# ESP32 register map
Vendor: ESPRESSIF SYSTEMS (SHANGHAI) CO., LTD.; Series: ESP32 Series; File version: 17
CPU: Xtensa LX6 r0p0, little endian, no MPU, FPU, 0 interrupt priority bits
Address unit: 32 bits
Registers are 32-bit, read-write, reset 0x0 unless marked. A register's access mark holds for its fields unless they carry their own. Offsets are from the block's base; [hi:lo] are bit positions; {n}, {i} and the like mark numbered series.

## SLCHOST — SLCHOST Peripheral
Base 0x3FF55000
0x10 HOST_SLCHOST_FUNC2_0
  [24] HOST_SLC_FUNC2_INT
0x14 HOST_SLCHOST_FUNC2_1
  [0] HOST_SLC_FUNC2_INT_EN
0x20 HOST_SLCHOST_FUNC2_2 reset 0x1
  [0] HOST_SLC_FUNC1_MDSTAT
0x34 HOST_SLCHOST_GPIO_STATUS0 ro
  [31:0] HOST_GPIO_SDIO_INT0
0x38 HOST_SLCHOST_GPIO_STATUS1 ro
  [7:0] HOST_GPIO_SDIO_INT1
0x3C HOST_SLCHOST_GPIO_IN0 ro
  [31:0] HOST_GPIO_SDIO_IN0
0x40 HOST_SLCHOST_GPIO_IN1 ro
  [7:0] HOST_GPIO_SDIO_IN1
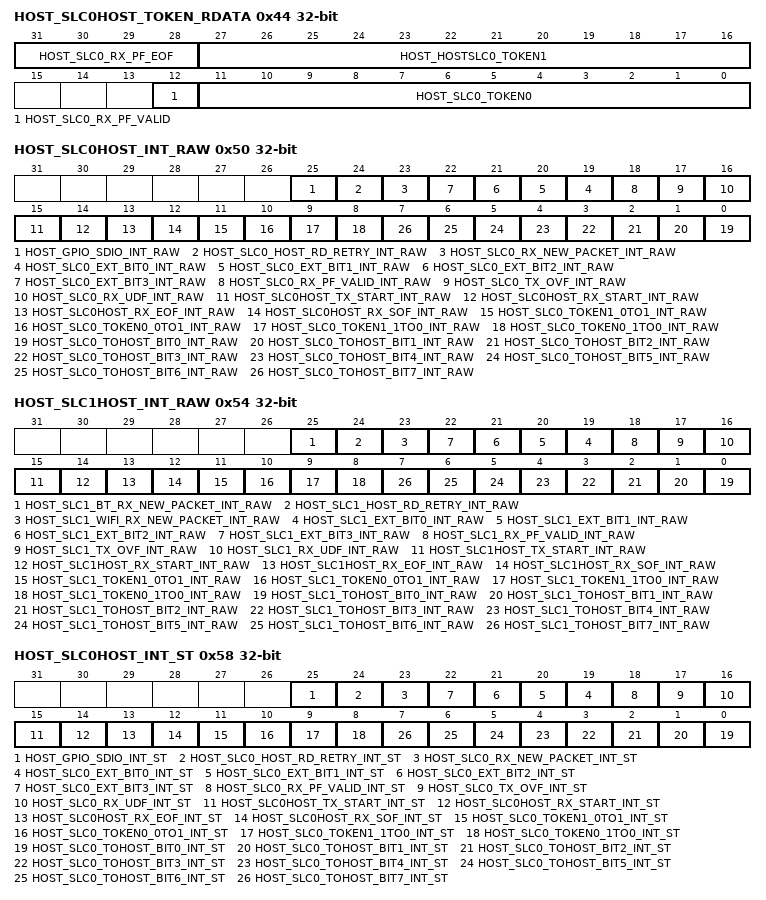
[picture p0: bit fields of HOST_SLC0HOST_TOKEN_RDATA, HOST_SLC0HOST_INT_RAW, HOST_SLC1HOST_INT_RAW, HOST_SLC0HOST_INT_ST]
0x44 HOST_SLC0HOST_TOKEN_RDATA ro
  [31:28] HOST_SLC0_RX_PF_EOF, [27:16] HOST_HOSTSLC0_TOKEN1, [12] HOST_SLC0_RX_PF_VALID, [11:0] HOST_SLC0_TOKEN0
0x48 HOST_SLC0_HOST_PF ro
  [31:0] HOST_SLC0_PF_DATA
0x4C HOST_SLC1_HOST_PF ro
  [31:0] HOST_SLC1_PF_DATA
0x50 HOST_SLC0HOST_INT_RAW ro
  [25] HOST_GPIO_SDIO_INT_RAW, [24] HOST_SLC0_HOST_RD_RETRY_INT_RAW, [23] HOST_SLC0_RX_NEW_PACKET_INT_RAW, [n+19] HOST_SLC0_EXT_BIT{n}_INT_RAW (n=0..3), [18] HOST_SLC0_RX_PF_VALID_INT_RAW, [17] HOST_SLC0_TX_OVF_INT_RAW, [16] HOST_SLC0_RX_UDF_INT_RAW, [15] HOST_SLC0HOST_TX_START_INT_RAW, [14] HOST_SLC0HOST_RX_START_INT_RAW, [13] HOST_SLC0HOST_RX_EOF_INT_RAW, [12] HOST_SLC0HOST_RX_SOF_INT_RAW, [11] HOST_SLC0_TOKEN1_0TO1_INT_RAW, [10] HOST_SLC0_TOKEN0_0TO1_INT_RAW, [9] HOST_SLC0_TOKEN1_1TO0_INT_RAW, [8] HOST_SLC0_TOKEN0_1TO0_INT_RAW, [n] HOST_SLC0_TOHOST_BIT{n}_INT_RAW (n=0..7)
0x54 HOST_SLC1HOST_INT_RAW ro
  [25] HOST_SLC1_BT_RX_NEW_PACKET_INT_RAW, [24] HOST_SLC1_HOST_RD_RETRY_INT_RAW, [23] HOST_SLC1_WIFI_RX_NEW_PACKET_INT_RAW, [n+19] HOST_SLC1_EXT_BIT{n}_INT_RAW (n=0..3), [18] HOST_SLC1_RX_PF_VALID_INT_RAW, [17] HOST_SLC1_TX_OVF_INT_RAW, [16] HOST_SLC1_RX_UDF_INT_RAW, [15] HOST_SLC1HOST_TX_START_INT_RAW, [14] HOST_SLC1HOST_RX_START_INT_RAW, [13] HOST_SLC1HOST_RX_EOF_INT_RAW, [12] HOST_SLC1HOST_RX_SOF_INT_RAW, [11] HOST_SLC1_TOKEN1_0TO1_INT_RAW, [10] HOST_SLC1_TOKEN0_0TO1_INT_RAW, [9] HOST_SLC1_TOKEN1_1TO0_INT_RAW, [8] HOST_SLC1_TOKEN0_1TO0_INT_RAW, [n] HOST_SLC1_TOHOST_BIT{n}_INT_RAW (n=0..7)
0x58 HOST_SLC0HOST_INT_ST ro
  [25] HOST_GPIO_SDIO_INT_ST, [24] HOST_SLC0_HOST_RD_RETRY_INT_ST, [23] HOST_SLC0_RX_NEW_PACKET_INT_ST, [n+19] HOST_SLC0_EXT_BIT{n}_INT_ST (n=0..3), [18] HOST_SLC0_RX_PF_VALID_INT_ST, [17] HOST_SLC0_TX_OVF_INT_ST, [16] HOST_SLC0_RX_UDF_INT_ST, [15] HOST_SLC0HOST_TX_START_INT_ST, [14] HOST_SLC0HOST_RX_START_INT_ST, [13] HOST_SLC0HOST_RX_EOF_INT_ST, [12] HOST_SLC0HOST_RX_SOF_INT_ST, [11] HOST_SLC0_TOKEN1_0TO1_INT_ST, [10] HOST_SLC0_TOKEN0_0TO1_INT_ST, [9] HOST_SLC0_TOKEN1_1TO0_INT_ST, [8] HOST_SLC0_TOKEN0_1TO0_INT_ST, [n] HOST_SLC0_TOHOST_BIT{n}_INT_ST (n=0..7)
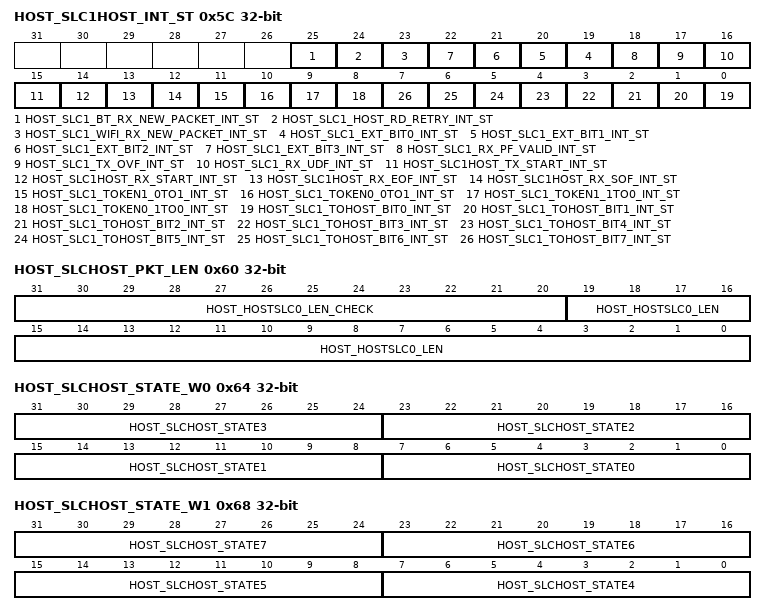
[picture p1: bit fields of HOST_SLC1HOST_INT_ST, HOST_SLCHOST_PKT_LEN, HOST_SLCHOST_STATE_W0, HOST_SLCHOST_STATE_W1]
0x5C HOST_SLC1HOST_INT_ST ro
  [25] HOST_SLC1_BT_RX_NEW_PACKET_INT_ST, [24] HOST_SLC1_HOST_RD_RETRY_INT_ST, [23] HOST_SLC1_WIFI_RX_NEW_PACKET_INT_ST, [n+19] HOST_SLC1_EXT_BIT{n}_INT_ST (n=0..3), [18] HOST_SLC1_RX_PF_VALID_INT_ST, [17] HOST_SLC1_TX_OVF_INT_ST, [16] HOST_SLC1_RX_UDF_INT_ST, [15] HOST_SLC1HOST_TX_START_INT_ST, [14] HOST_SLC1HOST_RX_START_INT_ST, [13] HOST_SLC1HOST_RX_EOF_INT_ST, [12] HOST_SLC1HOST_RX_SOF_INT_ST, [11] HOST_SLC1_TOKEN1_0TO1_INT_ST, [10] HOST_SLC1_TOKEN0_0TO1_INT_ST, [9] HOST_SLC1_TOKEN1_1TO0_INT_ST, [8] HOST_SLC1_TOKEN0_1TO0_INT_ST, [n] HOST_SLC1_TOHOST_BIT{n}_INT_ST (n=0..7)
0x60 HOST_SLCHOST_PKT_LEN ro
  [31:20] HOST_HOSTSLC0_LEN_CHECK, [19:0] HOST_HOSTSLC0_LEN
0x64 HOST_SLCHOST_STATE_W0 ro
  [8n+7:8n] HOST_SLCHOST_STATE{n} (n=0..3)
0x68 HOST_SLCHOST_STATE_W1 ro
  [8n-25:8n-32] HOST_SLCHOST_STATE{n} (n=4..7)
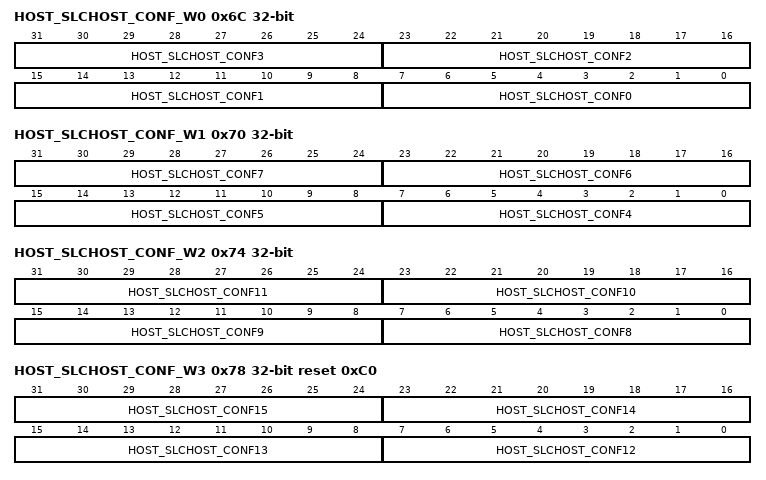
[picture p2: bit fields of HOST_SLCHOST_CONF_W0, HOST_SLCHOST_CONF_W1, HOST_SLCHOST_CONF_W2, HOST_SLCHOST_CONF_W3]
0x6C HOST_SLCHOST_CONF_W0
  [8n+7:8n] HOST_SLCHOST_CONF{n} (n=0..3)
0x70 HOST_SLCHOST_CONF_W1
  [8n-25:8n-32] HOST_SLCHOST_CONF{n} (n=4..7)
0x74 HOST_SLCHOST_CONF_W2
  [8n-57:8n-64] HOST_SLCHOST_CONF{n} (n=8..11)
0x78 HOST_SLCHOST_CONF_W3 reset 0xC0
  [8n-89:8n-96] HOST_SLCHOST_CONF{n} (n=12..15)
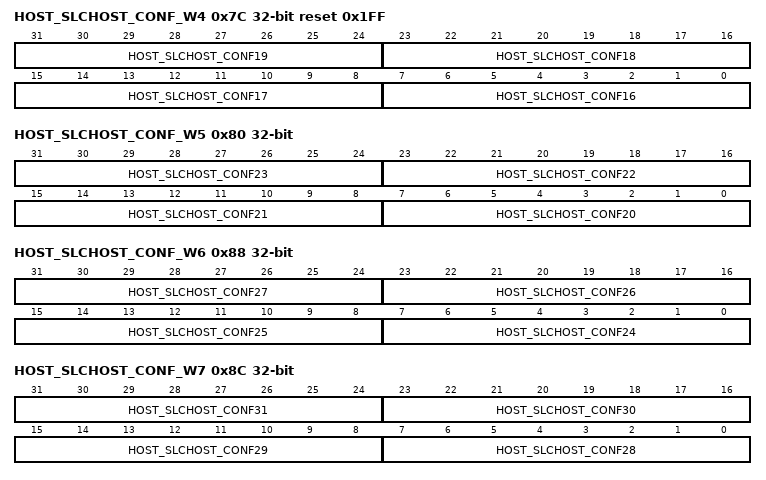
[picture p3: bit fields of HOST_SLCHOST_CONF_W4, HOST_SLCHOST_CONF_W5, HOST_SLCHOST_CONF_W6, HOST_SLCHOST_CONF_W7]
0x7C HOST_SLCHOST_CONF_W4 reset 0x1FF
  [31:24] HOST_SLCHOST_CONF19 — Interrupt to target CPU
  [23:16] HOST_SLCHOST_CONF18
  [15:8] HOST_SLCHOST_CONF17 — SLC timeout enable
  [7:0] HOST_SLCHOST_CONF16 — SLC timeout value
0x80 HOST_SLCHOST_CONF_W5
  [8n-153:8n-160] HOST_SLCHOST_CONF{n} (n=20..23)
0x84 HOST_SLCHOST_WIN_CMD access not given
0x88 HOST_SLCHOST_CONF_W6
  [8n-185:8n-192] HOST_SLCHOST_CONF{n} (n=24..27)
0x8C HOST_SLCHOST_CONF_W7
  [8n-217:8n-224] HOST_SLCHOST_CONF{n} (n=28..31)
{0x90+4i} HOST_SLCHOST_PKT_LEN{i} ro (i=0..2)
  [19:0] HOST_HOSTSLC0_LEN{i}
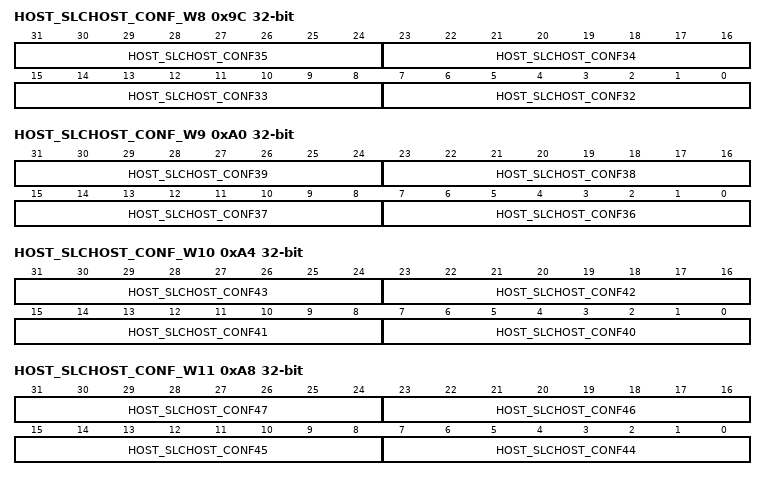
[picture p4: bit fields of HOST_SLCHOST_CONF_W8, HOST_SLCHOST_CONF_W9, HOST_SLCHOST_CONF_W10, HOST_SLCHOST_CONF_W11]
0x9C HOST_SLCHOST_CONF_W8
  [8n-249:8n-256] HOST_SLCHOST_CONF{n} (n=32..35)
0xA0 HOST_SLCHOST_CONF_W9
  [8n-281:8n-288] HOST_SLCHOST_CONF{n} (n=36..39)
0xA4 HOST_SLCHOST_CONF_W10
  [8n-313:8n-320] HOST_SLCHOST_CONF{n} (n=40..43)
0xA8 HOST_SLCHOST_CONF_W11
  [8n-345:8n-352] HOST_SLCHOST_CONF{n} (n=44..47)
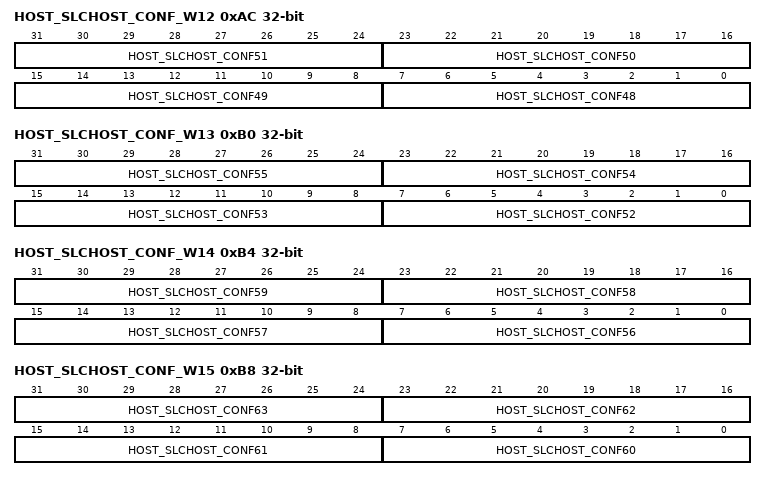
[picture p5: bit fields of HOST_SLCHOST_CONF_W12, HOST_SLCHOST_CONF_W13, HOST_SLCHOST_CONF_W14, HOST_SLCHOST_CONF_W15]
0xAC HOST_SLCHOST_CONF_W12
  [8n-377:8n-384] HOST_SLCHOST_CONF{n} (n=48..51)
0xB0 HOST_SLCHOST_CONF_W13
  [8n-409:8n-416] HOST_SLCHOST_CONF{n} (n=52..55)
0xB4 HOST_SLCHOST_CONF_W14
  [8n-441:8n-448] HOST_SLCHOST_CONF{n} (n=56..59)
0xB8 HOST_SLCHOST_CONF_W15
  [8n-473:8n-480] HOST_SLCHOST_CONF{n} (n=60..63)
0xBC HOST_SLCHOST_CHECK_SUM0 ro
0xC0 HOST_SLCHOST_CHECK_SUM1 ro
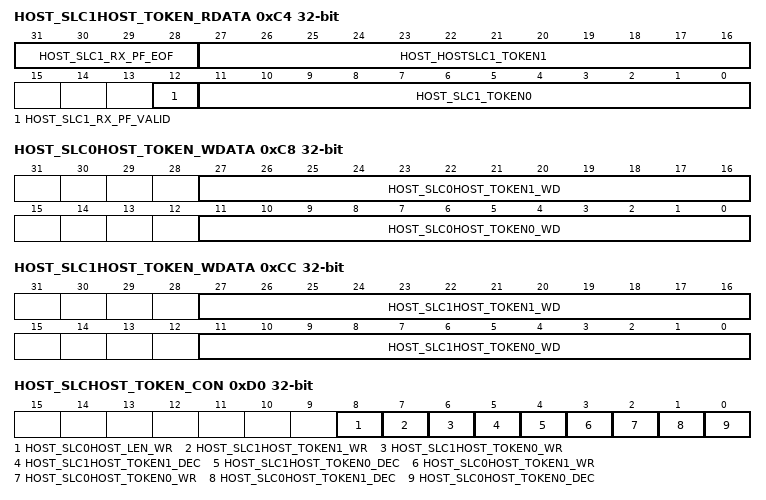
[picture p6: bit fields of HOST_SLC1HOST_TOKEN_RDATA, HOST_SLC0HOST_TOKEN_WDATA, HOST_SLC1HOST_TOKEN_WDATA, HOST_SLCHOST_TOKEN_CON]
0xC4 HOST_SLC1HOST_TOKEN_RDATA ro
  [31:28] HOST_SLC1_RX_PF_EOF, [27:16] HOST_HOSTSLC1_TOKEN1, [12] HOST_SLC1_RX_PF_VALID, [11:0] HOST_SLC1_TOKEN0
0xC8 HOST_SLC0HOST_TOKEN_WDATA
  [27:16] HOST_SLC0HOST_TOKEN1_WD, [11:0] HOST_SLC0HOST_TOKEN0_WD
0xCC HOST_SLC1HOST_TOKEN_WDATA
  [27:16] HOST_SLC1HOST_TOKEN1_WD, [11:0] HOST_SLC1HOST_TOKEN0_WD
0xD0 HOST_SLCHOST_TOKEN_CON wo
  [8] HOST_SLC0HOST_LEN_WR, [7] HOST_SLC1HOST_TOKEN1_WR, [6] HOST_SLC1HOST_TOKEN0_WR, [5] HOST_SLC1HOST_TOKEN1_DEC, [4] HOST_SLC1HOST_TOKEN0_DEC, [3] HOST_SLC0HOST_TOKEN1_WR, [2] HOST_SLC0HOST_TOKEN0_WR, [1] HOST_SLC0HOST_TOKEN1_DEC, [0] HOST_SLC0HOST_TOKEN0_DEC
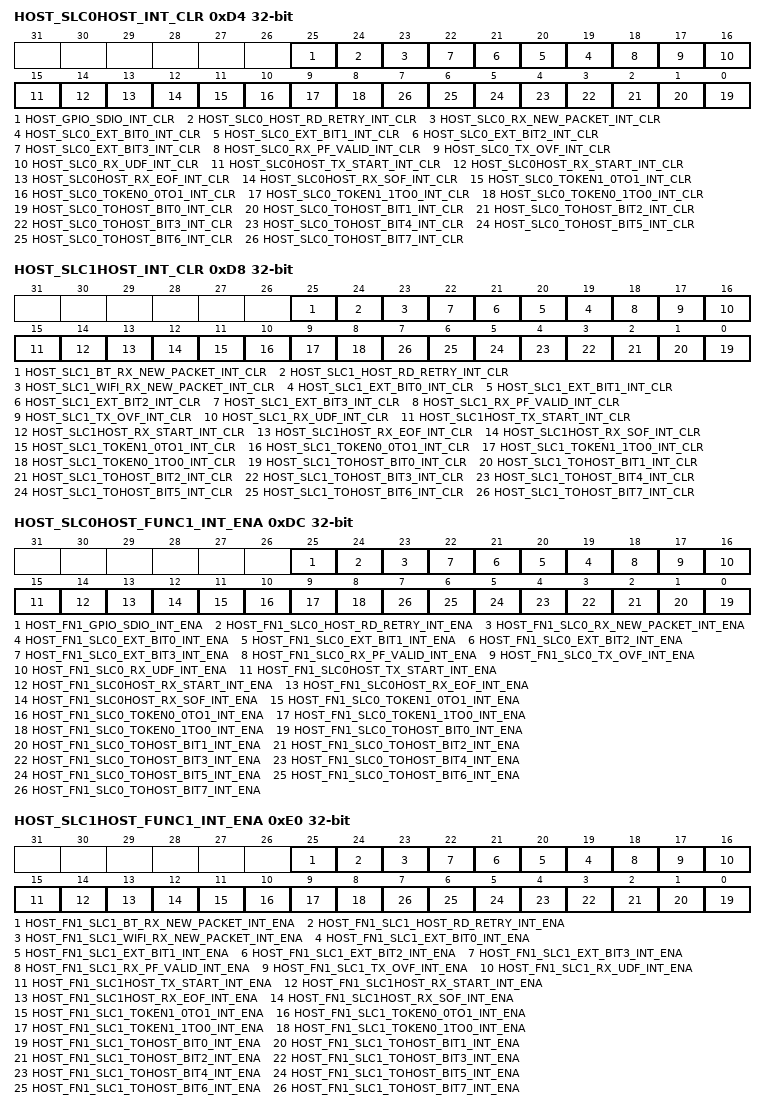
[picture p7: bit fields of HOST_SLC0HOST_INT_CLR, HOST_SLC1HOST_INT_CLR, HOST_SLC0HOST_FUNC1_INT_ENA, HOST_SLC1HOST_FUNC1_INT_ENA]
0xD4 HOST_SLC0HOST_INT_CLR wo
  [25] HOST_GPIO_SDIO_INT_CLR, [24] HOST_SLC0_HOST_RD_RETRY_INT_CLR, [23] HOST_SLC0_RX_NEW_PACKET_INT_CLR, [n+19] HOST_SLC0_EXT_BIT{n}_INT_CLR (n=0..3), [18] HOST_SLC0_RX_PF_VALID_INT_CLR, [17] HOST_SLC0_TX_OVF_INT_CLR, [16] HOST_SLC0_RX_UDF_INT_CLR, [15] HOST_SLC0HOST_TX_START_INT_CLR, [14] HOST_SLC0HOST_RX_START_INT_CLR, [13] HOST_SLC0HOST_RX_EOF_INT_CLR, [12] HOST_SLC0HOST_RX_SOF_INT_CLR, [11] HOST_SLC0_TOKEN1_0TO1_INT_CLR, [10] HOST_SLC0_TOKEN0_0TO1_INT_CLR, [9] HOST_SLC0_TOKEN1_1TO0_INT_CLR, [8] HOST_SLC0_TOKEN0_1TO0_INT_CLR, [n] HOST_SLC0_TOHOST_BIT{n}_INT_CLR (n=0..7)
0xD8 HOST_SLC1HOST_INT_CLR wo
  [25] HOST_SLC1_BT_RX_NEW_PACKET_INT_CLR, [24] HOST_SLC1_HOST_RD_RETRY_INT_CLR, [23] HOST_SLC1_WIFI_RX_NEW_PACKET_INT_CLR, [n+19] HOST_SLC1_EXT_BIT{n}_INT_CLR (n=0..3), [18] HOST_SLC1_RX_PF_VALID_INT_CLR, [17] HOST_SLC1_TX_OVF_INT_CLR, [16] HOST_SLC1_RX_UDF_INT_CLR, [15] HOST_SLC1HOST_TX_START_INT_CLR, [14] HOST_SLC1HOST_RX_START_INT_CLR, [13] HOST_SLC1HOST_RX_EOF_INT_CLR, [12] HOST_SLC1HOST_RX_SOF_INT_CLR, [11] HOST_SLC1_TOKEN1_0TO1_INT_CLR, [10] HOST_SLC1_TOKEN0_0TO1_INT_CLR, [9] HOST_SLC1_TOKEN1_1TO0_INT_CLR, [8] HOST_SLC1_TOKEN0_1TO0_INT_CLR, [n] HOST_SLC1_TOHOST_BIT{n}_INT_CLR (n=0..7)
0xDC HOST_SLC0HOST_FUNC1_INT_ENA
  [25] HOST_FN1_GPIO_SDIO_INT_ENA, [24] HOST_FN1_SLC0_HOST_RD_RETRY_INT_ENA, [23] HOST_FN1_SLC0_RX_NEW_PACKET_INT_ENA, [n+19] HOST_FN1_SLC0_EXT_BIT{n}_INT_ENA (n=0..3), [18] HOST_FN1_SLC0_RX_PF_VALID_INT_ENA, [17] HOST_FN1_SLC0_TX_OVF_INT_ENA, [16] HOST_FN1_SLC0_RX_UDF_INT_ENA, [15] HOST_FN1_SLC0HOST_TX_START_INT_ENA, [14] HOST_FN1_SLC0HOST_RX_START_INT_ENA, [13] HOST_FN1_SLC0HOST_RX_EOF_INT_ENA, [12] HOST_FN1_SLC0HOST_RX_SOF_INT_ENA, [11] HOST_FN1_SLC0_TOKEN1_0TO1_INT_ENA, [10] HOST_FN1_SLC0_TOKEN0_0TO1_INT_ENA, [9] HOST_FN1_SLC0_TOKEN1_1TO0_INT_ENA, [8] HOST_FN1_SLC0_TOKEN0_1TO0_INT_ENA, [n] HOST_FN1_SLC0_TOHOST_BIT{n}_INT_ENA (n=0..7)
0xE0 HOST_SLC1HOST_FUNC1_INT_ENA
  [25] HOST_FN1_SLC1_BT_RX_NEW_PACKET_INT_ENA, [24] HOST_FN1_SLC1_HOST_RD_RETRY_INT_ENA, [23] HOST_FN1_SLC1_WIFI_RX_NEW_PACKET_INT_ENA, [n+19] HOST_FN1_SLC1_EXT_BIT{n}_INT_ENA (n=0..3), [18] HOST_FN1_SLC1_RX_PF_VALID_INT_ENA, [17] HOST_FN1_SLC1_TX_OVF_INT_ENA, [16] HOST_FN1_SLC1_RX_UDF_INT_ENA, [15] HOST_FN1_SLC1HOST_TX_START_INT_ENA, [14] HOST_FN1_SLC1HOST_RX_START_INT_ENA, [13] HOST_FN1_SLC1HOST_RX_EOF_INT_ENA, [12] HOST_FN1_SLC1HOST_RX_SOF_INT_ENA, [11] HOST_FN1_SLC1_TOKEN1_0TO1_INT_ENA, [10] HOST_FN1_SLC1_TOKEN0_0TO1_INT_ENA, [9] HOST_FN1_SLC1_TOKEN1_1TO0_INT_ENA, [8] HOST_FN1_SLC1_TOKEN0_1TO0_INT_ENA, [n] HOST_FN1_SLC1_TOHOST_BIT{n}_INT_ENA (n=0..7)
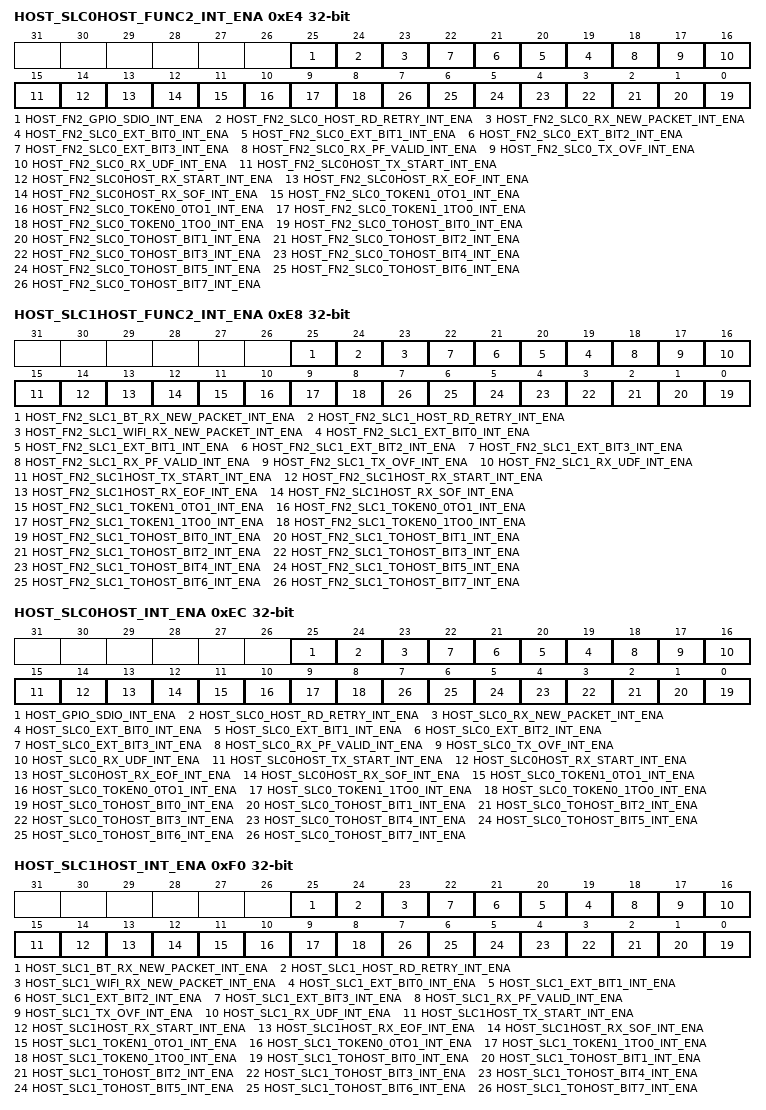
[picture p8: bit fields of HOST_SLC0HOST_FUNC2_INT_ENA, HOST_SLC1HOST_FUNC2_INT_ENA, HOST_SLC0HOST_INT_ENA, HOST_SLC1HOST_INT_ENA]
0xE4 HOST_SLC0HOST_FUNC2_INT_ENA
  [25] HOST_FN2_GPIO_SDIO_INT_ENA, [24] HOST_FN2_SLC0_HOST_RD_RETRY_INT_ENA, [23] HOST_FN2_SLC0_RX_NEW_PACKET_INT_ENA, [n+19] HOST_FN2_SLC0_EXT_BIT{n}_INT_ENA (n=0..3), [18] HOST_FN2_SLC0_RX_PF_VALID_INT_ENA, [17] HOST_FN2_SLC0_TX_OVF_INT_ENA, [16] HOST_FN2_SLC0_RX_UDF_INT_ENA, [15] HOST_FN2_SLC0HOST_TX_START_INT_ENA, [14] HOST_FN2_SLC0HOST_RX_START_INT_ENA, [13] HOST_FN2_SLC0HOST_RX_EOF_INT_ENA, [12] HOST_FN2_SLC0HOST_RX_SOF_INT_ENA, [11] HOST_FN2_SLC0_TOKEN1_0TO1_INT_ENA, [10] HOST_FN2_SLC0_TOKEN0_0TO1_INT_ENA, [9] HOST_FN2_SLC0_TOKEN1_1TO0_INT_ENA, [8] HOST_FN2_SLC0_TOKEN0_1TO0_INT_ENA, [n] HOST_FN2_SLC0_TOHOST_BIT{n}_INT_ENA (n=0..7)
0xE8 HOST_SLC1HOST_FUNC2_INT_ENA
  [25] HOST_FN2_SLC1_BT_RX_NEW_PACKET_INT_ENA, [24] HOST_FN2_SLC1_HOST_RD_RETRY_INT_ENA, [23] HOST_FN2_SLC1_WIFI_RX_NEW_PACKET_INT_ENA, [n+19] HOST_FN2_SLC1_EXT_BIT{n}_INT_ENA (n=0..3), [18] HOST_FN2_SLC1_RX_PF_VALID_INT_ENA, [17] HOST_FN2_SLC1_TX_OVF_INT_ENA, [16] HOST_FN2_SLC1_RX_UDF_INT_ENA, [15] HOST_FN2_SLC1HOST_TX_START_INT_ENA, [14] HOST_FN2_SLC1HOST_RX_START_INT_ENA, [13] HOST_FN2_SLC1HOST_RX_EOF_INT_ENA, [12] HOST_FN2_SLC1HOST_RX_SOF_INT_ENA, [11] HOST_FN2_SLC1_TOKEN1_0TO1_INT_ENA, [10] HOST_FN2_SLC1_TOKEN0_0TO1_INT_ENA, [9] HOST_FN2_SLC1_TOKEN1_1TO0_INT_ENA, [8] HOST_FN2_SLC1_TOKEN0_1TO0_INT_ENA, [n] HOST_FN2_SLC1_TOHOST_BIT{n}_INT_ENA (n=0..7)
0xEC HOST_SLC0HOST_INT_ENA
  [25] HOST_GPIO_SDIO_INT_ENA, [24] HOST_SLC0_HOST_RD_RETRY_INT_ENA, [23] HOST_SLC0_RX_NEW_PACKET_INT_ENA, [n+19] HOST_SLC0_EXT_BIT{n}_INT_ENA (n=0..3), [18] HOST_SLC0_RX_PF_VALID_INT_ENA, [17] HOST_SLC0_TX_OVF_INT_ENA, [16] HOST_SLC0_RX_UDF_INT_ENA, [15] HOST_SLC0HOST_TX_START_INT_ENA, [14] HOST_SLC0HOST_RX_START_INT_ENA, [13] HOST_SLC0HOST_RX_EOF_INT_ENA, [12] HOST_SLC0HOST_RX_SOF_INT_ENA, [11] HOST_SLC0_TOKEN1_0TO1_INT_ENA, [10] HOST_SLC0_TOKEN0_0TO1_INT_ENA, [9] HOST_SLC0_TOKEN1_1TO0_INT_ENA, [8] HOST_SLC0_TOKEN0_1TO0_INT_ENA, [n] HOST_SLC0_TOHOST_BIT{n}_INT_ENA (n=0..7)
0xF0 HOST_SLC1HOST_INT_ENA
  [25] HOST_SLC1_BT_RX_NEW_PACKET_INT_ENA, [24] HOST_SLC1_HOST_RD_RETRY_INT_ENA, [23] HOST_SLC1_WIFI_RX_NEW_PACKET_INT_ENA, [n+19] HOST_SLC1_EXT_BIT{n}_INT_ENA (n=0..3), [18] HOST_SLC1_RX_PF_VALID_INT_ENA, [17] HOST_SLC1_TX_OVF_INT_ENA, [16] HOST_SLC1_RX_UDF_INT_ENA, [15] HOST_SLC1HOST_TX_START_INT_ENA, [14] HOST_SLC1HOST_RX_START_INT_ENA, [13] HOST_SLC1HOST_RX_EOF_INT_ENA, [12] HOST_SLC1HOST_RX_SOF_INT_ENA, [11] HOST_SLC1_TOKEN1_0TO1_INT_ENA, [10] HOST_SLC1_TOKEN0_0TO1_INT_ENA, [9] HOST_SLC1_TOKEN1_1TO0_INT_ENA, [8] HOST_SLC1_TOKEN0_1TO0_INT_ENA, [n] HOST_SLC1_TOHOST_BIT{n}_INT_ENA (n=0..7)
0xF4 HOST_SLC0HOST_RX_INFOR
  [19:0] HOST_SLC0HOST_RX_INFOR
0xF8 HOST_SLC1HOST_RX_INFOR
  [19:0] HOST_SLC1HOST_RX_INFOR
0xFC HOST_SLC0HOST_LEN_WD
0x100 HOST_SLC_APBWIN_WDATA
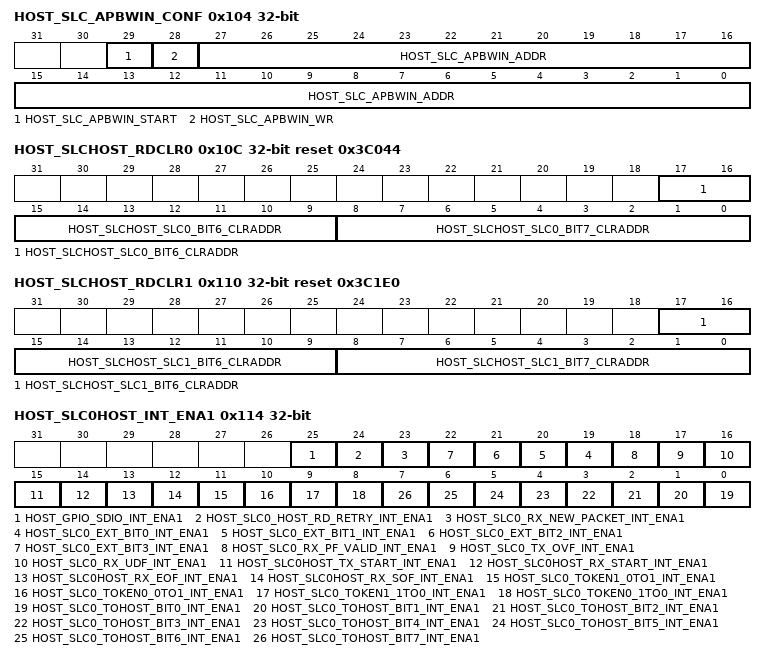
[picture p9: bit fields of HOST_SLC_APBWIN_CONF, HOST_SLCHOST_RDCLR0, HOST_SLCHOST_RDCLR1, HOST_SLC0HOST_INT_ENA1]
0x104 HOST_SLC_APBWIN_CONF
  [29] HOST_SLC_APBWIN_START, [28] HOST_SLC_APBWIN_WR, [27:0] HOST_SLC_APBWIN_ADDR
0x108 HOST_SLC_APBWIN_RDATA ro
0x10C HOST_SLCHOST_RDCLR0 reset 0x3C044
  [17:9] HOST_SLCHOST_SLC0_BIT6_CLRADDR, [8:0] HOST_SLCHOST_SLC0_BIT7_CLRADDR
0x110 HOST_SLCHOST_RDCLR1 reset 0x3C1E0
  [17:9] HOST_SLCHOST_SLC1_BIT6_CLRADDR, [8:0] HOST_SLCHOST_SLC1_BIT7_CLRADDR
0x114 HOST_SLC0HOST_INT_ENA1
  [25] HOST_GPIO_SDIO_INT_ENA1, [24] HOST_SLC0_HOST_RD_RETRY_INT_ENA1, [23] HOST_SLC0_RX_NEW_PACKET_INT_ENA1, [n+19] HOST_SLC0_EXT_BIT{n}_INT_ENA1 (n=0..3), [18] HOST_SLC0_RX_PF_VALID_INT_ENA1, [17] HOST_SLC0_TX_OVF_INT_ENA1, [16] HOST_SLC0_RX_UDF_INT_ENA1, [15] HOST_SLC0HOST_TX_START_INT_ENA1, [14] HOST_SLC0HOST_RX_START_INT_ENA1, [13] HOST_SLC0HOST_RX_EOF_INT_ENA1, [12] HOST_SLC0HOST_RX_SOF_INT_ENA1, [11] HOST_SLC0_TOKEN1_0TO1_INT_ENA1, [10] HOST_SLC0_TOKEN0_0TO1_INT_ENA1, [9] HOST_SLC0_TOKEN1_1TO0_INT_ENA1, [8] HOST_SLC0_TOKEN0_1TO0_INT_ENA1, [n] HOST_SLC0_TOHOST_BIT{n}_INT_ENA1 (n=0..7)
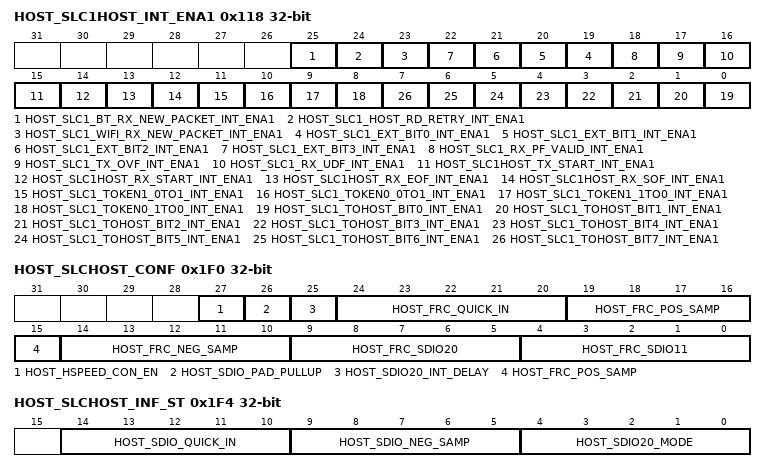
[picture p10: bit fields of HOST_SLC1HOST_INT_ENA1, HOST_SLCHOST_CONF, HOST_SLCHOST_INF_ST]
0x118 HOST_SLC1HOST_INT_ENA1
  [25] HOST_SLC1_BT_RX_NEW_PACKET_INT_ENA1, [24] HOST_SLC1_HOST_RD_RETRY_INT_ENA1, [23] HOST_SLC1_WIFI_RX_NEW_PACKET_INT_ENA1, [n+19] HOST_SLC1_EXT_BIT{n}_INT_ENA1 (n=0..3), [18] HOST_SLC1_RX_PF_VALID_INT_ENA1, [17] HOST_SLC1_TX_OVF_INT_ENA1, [16] HOST_SLC1_RX_UDF_INT_ENA1, [15] HOST_SLC1HOST_TX_START_INT_ENA1, [14] HOST_SLC1HOST_RX_START_INT_ENA1, [13] HOST_SLC1HOST_RX_EOF_INT_ENA1, [12] HOST_SLC1HOST_RX_SOF_INT_ENA1, [11] HOST_SLC1_TOKEN1_0TO1_INT_ENA1, [10] HOST_SLC1_TOKEN0_0TO1_INT_ENA1, [9] HOST_SLC1_TOKEN1_1TO0_INT_ENA1, [8] HOST_SLC1_TOKEN0_1TO0_INT_ENA1, [n] HOST_SLC1_TOHOST_BIT{n}_INT_ENA1 (n=0..7)
0x178 HOST_SLCHOSTDATE reset 0x16022500
  [31:0] HOST_SLCHOST_DATE
0x17C HOST_SLCHOSTID reset 0x600
  [31:0] HOST_SLCHOST_ID
0x1F0 HOST_SLCHOST_CONF
  [27] HOST_HSPEED_CON_EN, [26] HOST_SDIO_PAD_PULLUP, [25] HOST_SDIO20_INT_DELAY, [24:20] HOST_FRC_QUICK_IN, [19:15] HOST_FRC_POS_SAMP, [14:10] HOST_FRC_NEG_SAMP, [9:5] HOST_FRC_SDIO20, [4:0] HOST_FRC_SDIO11
0x1F4 HOST_SLCHOST_INF_ST ro
  [14:10] HOST_SDIO_QUICK_IN, [9:5] HOST_SDIO_NEG_SAMP, [4:0] HOST_SDIO20_MODE
